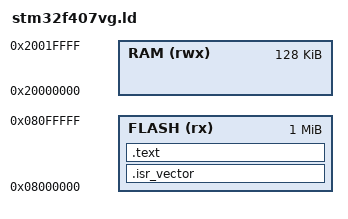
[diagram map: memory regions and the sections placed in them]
// ELF entrypoint
ENTRY(Reset_Handler)

// address are not arbitrary, follows STM32F407VG memory map
MEMORY
{
    FLASH (rx)  : ORIGIN = 0x08000000, LENGTH = 1M
    RAM   (rwx) : ORIGIN = 0x20000000, LENGTH = 128K
}

_estack = ORIGIN(RAM) + LENGTH(RAM);

SECTIONS
{
    .isr_vector :
    {
        . = ALIGN(4);
        KEEP(*(.isr_vector))
        . = ALIGN(4);
    } > FLASH

    .text :
    {
        . = ALIGN(4);
        *(.text)
        *(.text.*)
        *(.rodata)
        *(.rodata.*)
        . = ALIGN(4);
    } > FLASH
}
